# AVR32SD28 register map
Vendor: Atmel; File version: 1.0
CPU: other r0p0, little endian, no MPU, no FPU, 4 interrupt priority bits
Registers are 8-bit, read-write, reset 0x0 unless marked. A register's access mark holds for its fields unless they carry their own. Offsets are from the block's base; [hi:lo] are bit positions; {n}, {i} and the like mark numbered series; 'fields as' and 'values as' point back to an identical list.

## EVSYS — Event System
Base 0x00800200
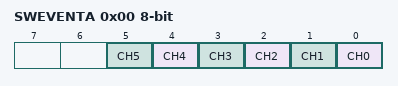
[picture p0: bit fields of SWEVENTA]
0x00 SWEVENTA wo — Software Event A
  [n] CH{n} (n=0..5) — Channel {n} Select
{0x10+i} CHANNEL{i} (i=0..5) — Multiplexer Channel {i}
  [7:0] CHANNEL — Channel Generator Select
    0=OFF; 1=UPDI_SYNCH (UPDI SYNCH character); 3=WDT_TICK (WDT LSB Tick); 4=SWDT_ERROR; 5=MVIO_VDDIO2OK (VDDIO2 OK); 6=RTC_OVF (Real Time Counter overflow); 7=RTC_CMP (Real Time Counter compare); 8=RTC_EVGEN0 (Event output 0); 9=RTC_EVGEN1 (Event output 1); {v}=CCL_LUT{v-16} (Configurable Custom Logic LUT{v-16}) (v=16..21); 32=AC0_OUT (Analog Comparator 0 out); 33=AC1_OUT (Analog Comparator 1 out); 34=AC2_OUT (Analog Comparator 2 out); 36=ADC0_RESRDY (ADC 0 Result Ready); 37=ADC0_SAMPRDY (ADC 0 Sample Ready); 38=ADC0_WCMP (ADC 0 Window Comparator); 39=ADC1_RESRDY (ADC 1 Result Ready); 40=ADC1_SAMPRDY (ADC 1 Sample Ready); 41=ADC1_WCMP (ADC 1 Window Comparator); 48=ZCD0_OUT (Zero Cross Detect 0 out); 51=ZCD3_OUT (Zero Cross Detect 3 out); 64=PORTA_EVGEN0 (Port A Event 0); 65=PORTA_EVGEN1 (Port A Event 1); 68=PORTC_EVGEN0 (Port C Event 0); 69=PORTC_EVGEN1 (Port C Event 1); 70=PORTD_EVGEN0 (Port D Event 0); 71=PORTD_EVGEN1 (Port D Event 1); 74=PORTF_EVGEN0 (Port F Event 0); 75=PORTF_EVGEN1 (Port F Event 1); 96=USART0_XCK; 97=USART1_XCK; 98=USART2_XCK; 104=SPI0_SCK; 105=SPI1_SCK; 128=TCA0_OVF_LUNF (Timer/Counter A0 overflow / low byte timer underflow); 129=TCA0_HUNF (Timer/Counter A0 high byte timer underflow); 132=TCA0_CMP0_LCMP0 (Timer/Counter A0 compare 0 / low byte timer compare 0); 133=TCA0_CMP1_LCMP1 (Timer/Counter A0 compare 0 / low byte timer compare 1); 134=TCA0_CMP2_LCMP2 (Timer/Counter A0 compare 0 / low byte timer compare 2); 160=TCB0_CAPT (Timer/Counter B0 capture); 161=TCB0_OVF (Timer/Counter B0 overflow); 162=TCB1_CAPT (Timer/Counter B1 capture); 163=TCB1_OVF (Timer/Counter B1 overflow); 164=TCB2_CAPT (Timer/Counter B2 capture); 165=TCB2_OVF (Timer/Counter B2 overflow); 166=TCB3_CAPT (Timer/Counter B3 capture); 167=TCB3_OVF (Timer/Counter B3 overflow); 176=TCD0_CMPBCLR (Counter matches CMPBCLR); 177=TCD0_CMPASET (Counter matches CMPASET); 178=TCD0_CMPBSET (Counter matches CMPBSET); 179=TCD0_PROGEV (Programmable event output)
{0x20+2i} USERCCLLUT{i}A (i=0..5) — User {2i} - CCL LUT{i} Event A
  [7:0] USER — User channel select
    0=OFF; {v}=CHANNEL{v-1} (Connect user to event channel {v-1}) (v=1..6)
{0x21+2i} USERCCLLUT{i}B (i=0..5) — User {2i+1} - CCL LUT{i} Event B
  fields as USERCCLLUT0A
0x2C USERADC0START — User 12 - ADC0
  fields as USERCCLLUT0A
0x2D USERADC1START — User 13 - ADC1
  fields as USERCCLLUT0A
0x2E USEREVSYSEVOUTA — User 14 - EVOUTA
  fields as USERCCLLUT0A
0x2F USEREVSYSEVOUTC — User 15 - EVOUTC
  fields as USERCCLLUT0A
0x30 USEREVSYSEVOUTD — User 16 - EVOUTD
  fields as USERCCLLUT0A
{0x32+i} USERUSART{i}IRDA (i=0..2) — User {i+18} - USART{i}
  fields as USERCCLLUT0A
0x35 USERTCA0CNTA — User 21 - TCA0 Event A
  fields as USERCCLLUT0A
0x36 USERTCA0CNTB — User 22 - TCA0 Event B
  fields as USERCCLLUT0A
{0x37+2i} USERTCB{i}CAPT (i=0..3) — User {2i+23} - TCB{i} Event A
  fields as USERCCLLUT0A
{0x38+2i} USERTCB{i}COUNT (i=0..3) — User {2i+24} - TCB{i} Event B
  fields as USERCCLLUT0A
0x3F USERTCD0INPUTA — User 31 - TCD0 Event A
  fields as USERCCLLUT0A
0x40 USERTCD0INPUTB — User 32 - TCD0 Event B
  fields as USERCCLLUT0A
0x41 USERERRCTRLEVENT0 — User 33 - ERRCTRL Event 0
  fields as USERCCLLUT0A
0x42 USERERRCTRLEVENT1 — User 34 - ERRCTRL Event 1
  fields as USERCCLLUT0A
0x43 USERCLKCTRLCFD — User 35 - CLKCTRL CFD
  fields as USERCCLLUT0A
0x44 USERCLKCTRLCFM — User 36 - CLKCTRL CFM
  fields as USERCCLLUT0A

## GPR — General Purpose Registers
Base 0x0080001C
{0x0+i} GPR{i} (i=0..3) — General Purpose Register {i}
